# StarFive VisionFive 2 v1.3b register map
File version: 0.1
Registers are 32-bit, read-write, no defined reset value unless marked. A register's access mark holds for its fields unless they carry their own. Offsets are from the block's base; [hi:lo] are bit positions; {n}, {i} and the like mark numbered series.

## starfive_jh7110_aon_pinctrl_0 — From starfive,jh7110-aon-pinctrl, peripheral generator
Base 0x17020000
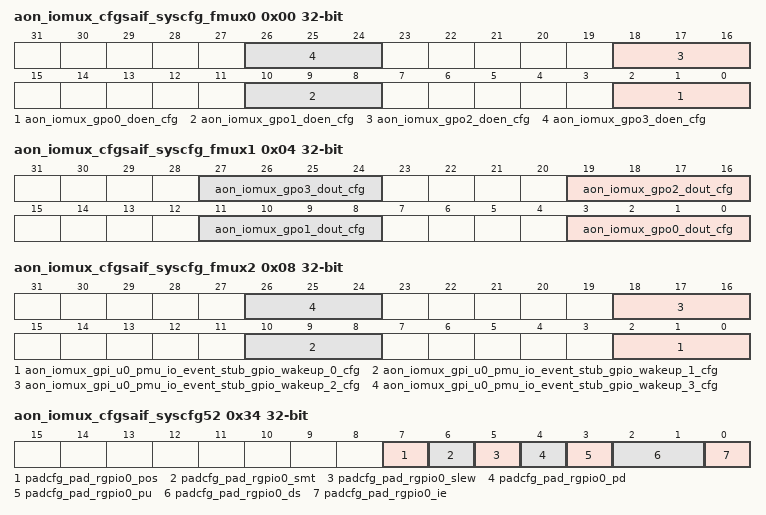
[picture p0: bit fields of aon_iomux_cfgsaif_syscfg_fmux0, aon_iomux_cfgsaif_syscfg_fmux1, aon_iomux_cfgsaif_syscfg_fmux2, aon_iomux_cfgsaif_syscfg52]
0x00 aon_iomux_cfgsaif_syscfg_fmux0
  [8n+2:8n] aon_iomux_gpo{n}_doen_cfg (n=0..3) — The selected OEN signal for GPIO{n}. The register value indicates the selected GPIO (Output Enable) OEN index from GPIO OEN list 0-5. See Table 2-42: GPIO OEN List for AON_IOMUX for more information.
0x04 aon_iomux_cfgsaif_syscfg_fmux1
  [8n+3:8n] aon_iomux_gpo{n}_dout_cfg (n=0..3) — The selected OEN signal for GPIO{n}. The register value indicates the selected GPIO output signal list 0-9. See Table 2-42: GPIO OEN List for AON_IOMUX for more information.
0x08 aon_iomux_cfgsaif_syscfg_fmux2
  [8n+2:8n] aon_iomux_gpi_u0_pmu_io_event_stub_gpio_wakeup_{n}_cfg (n=0..3) — The register value indicates the selected GPIO number + 2 (GPIO2-GPIO63, GPIO0 and GPIO1 are not available) for the input signal.
0x0C aon_iomux_cfgsaif_syscfg_fmux3
  [0] aon_gpioen_0_reg — Enable GPIO IRQ function.
0x10 aon_iomux_cfgsaif_syscfg_ioirq4
  [3:0] aon_gpiois_0_reg — 1: Edge trigger, 0: Level trigger
0x14 aon_iomux_cfgsaif_syscfg_ioirq5
  [3:0] aon_gpioic_0_reg — 1: Do not clear the register, 0: Clear the register
0x18 aon_iomux_cfgsaif_syscfg_ioirq6
  [3:0] aon_gpioibe_0_reg — 1: Trigger on both edges, 0: Trigger on a single edge
0x1C aon_iomux_cfgsaif_syscfg_ioirq7
  [3:0] aon_gpioiev_0_reg — 1: Positive/Low, 0: Negative/High
0x20 aon_iomux_cfgsaif_syscfg_ioirq8
  [3:0] aon_gpioie_0_reg — 1: Unmask, 0: Mask
0x24 aon_iomux_cfgsaif_syscfg_ioirq9
  [3:0] aon_gpioris_0_reg ro — Status of the edge trigger, can be cleared by writing gpioic.
0x28 aon_iomux_cfgsaif_syscfg_ioirq10
  [3:0] aon_gpiomis_0_reg ro — The masked GPIO IRQ status.
0x2C aon_iomux_cfgsaif_syscfg_ioirq11
  [3:0] aon_gpio_in_sync2_0_reg ro — Status of gpio_in after synchronization.
0x30 aon_iomux_cfgsaif_syscfg48
  [0] padcfg_pad_testen_pos — Power-on-Start (POS) enabler - 1: Enable active pull down for loss of core power, 0: Active pull-down capability disabled
0x34 aon_iomux_cfgsaif_syscfg52
  [7] padcfg_pad_rgpio0_pos — Power-on-Start (POS) enabler - 1: Enable active pull down for loss of core power, 0: Active pull-down capability disabled
  [6] padcfg_pad_rgpio0_smt — Active high Schmitt (SMT) trigger selector - 0: No hysteresis, 1: Schmitt trigger ebabled
  [5] padcfg_pad_rgpio0_slew — Slew Rate Control - 0: Slow (Half frequency), 1: Fast
  [4] padcfg_pad_rgpio0_pd — Pull-Down (PD) settings - 1: Yes, 0: No
  [3] padcfg_pad_rgpio0_pu — Pull-Up (PU) settings - 1: Yes, 0: No
  [2:1] padcfg_pad_rgpio0_ds — Output Drive Strength (DS) - 00: The rated drive strength is 2 mA, 01: The rated drive strength is 4 mA, 10: The rated drive strength is 8 mA, 11: The rated drive strength is 12 mA
  [0] padcfg_pad_rgpio0_ie — Input Enable (IE) Controller - 1: Enable the receiver, 0: Disable the receiver
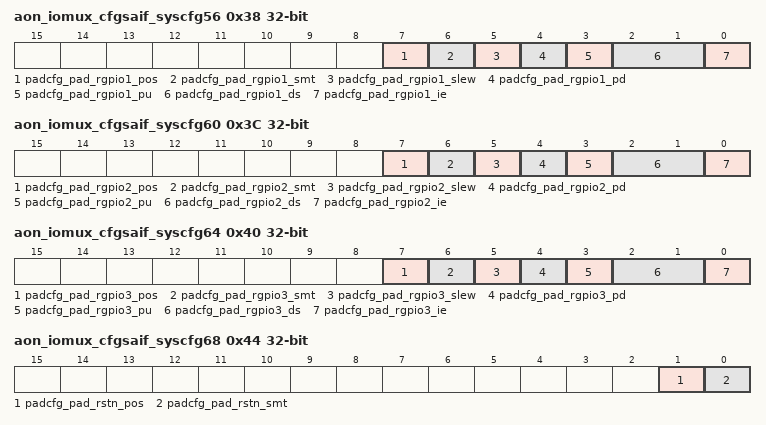
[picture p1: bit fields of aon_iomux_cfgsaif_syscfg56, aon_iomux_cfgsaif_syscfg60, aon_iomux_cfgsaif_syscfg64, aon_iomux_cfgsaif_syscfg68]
0x38 aon_iomux_cfgsaif_syscfg56
  [7] padcfg_pad_rgpio1_pos — Power-on-Start (POS) enabler - 1: Enable active pull down for loss of core power, 0: Active pull-down capability disabled
  [6] padcfg_pad_rgpio1_smt — Active high Schmitt (SMT) trigger selector - 0: No hysteresis, 1: Schmitt trigger ebabled
  [5] padcfg_pad_rgpio1_slew — Slew Rate Control - 0: Slow (Half frequency), 1: Fast
  [4] padcfg_pad_rgpio1_pd — Pull-Down (PD) settings - 1: Yes, 0: No
  [3] padcfg_pad_rgpio1_pu — Pull-Up (PU) settings - 1: Yes, 0: No
  [2:1] padcfg_pad_rgpio1_ds — Output Drive Strength (DS) - 00: The rated drive strength is 2 mA, 01: The rated drive strength is 4 mA, 10: The rated drive strength is 8 mA, 11: The rated drive strength is 12 mA
  [0] padcfg_pad_rgpio1_ie — Input Enable (IE) Controller - 1: Enable the receiver, 0: Disable the receiver
0x3C aon_iomux_cfgsaif_syscfg60
  [7] padcfg_pad_rgpio2_pos — Power-on-Start (POS) enabler - 1: Enable active pull down for loss of core power, 0: Active pull-down capability disabled
  [6] padcfg_pad_rgpio2_smt — Active high Schmitt (SMT) trigger selector - 0: No hysteresis, 1: Schmitt trigger ebabled
  [5] padcfg_pad_rgpio2_slew — Slew Rate Control - 0: Slow (Half frequency), 1: Fast
  [4] padcfg_pad_rgpio2_pd — Pull-Down (PD) settings - 1: Yes, 0: No
  [3] padcfg_pad_rgpio2_pu — Pull-Up (PU) settings - 1: Yes, 0: No
  [2:1] padcfg_pad_rgpio2_ds — Output Drive Strength (DS) - 00: The rated drive strength is 2 mA, 01: The rated drive strength is 4 mA, 10: The rated drive strength is 8 mA, 11: The rated drive strength is 12 mA
  [0] padcfg_pad_rgpio2_ie — Input Enable (IE) Controller - 1: Enable the receiver, 0: Disable the receiver
0x40 aon_iomux_cfgsaif_syscfg64
  [7] padcfg_pad_rgpio3_pos — Power-on-Start (POS) enabler - 1: Enable active pull down for loss of core power, 0: Active pull-down capability disabled
  [6] padcfg_pad_rgpio3_smt — Active high Schmitt (SMT) trigger selector - 0: No hysteresis, 1: Schmitt trigger ebabled
  [5] padcfg_pad_rgpio3_slew — Slew Rate Control - 0: Slow (Half frequency), 1: Fast
  [4] padcfg_pad_rgpio3_pd — Pull-Down (PD) settings - 1: Yes, 0: No
  [3] padcfg_pad_rgpio3_pu — Pull-Up (PU) settings - 1: Yes, 0: No
  [2:1] padcfg_pad_rgpio3_ds — Output Drive Strength (DS) - 00: The rated drive strength is 2 mA, 01: The rated drive strength is 4 mA, 10: The rated drive strength is 8 mA, 11: The rated drive strength is 12 mA
  [0] padcfg_pad_rgpio3_ie — Input Enable (IE) Controller - 1: Enable the receiver, 0: Disable the receiver
0x44 aon_iomux_cfgsaif_syscfg68
  [1] padcfg_pad_rstn_pos — Power-on-Start (POS) enabler - 1: Enable active pull-down for loss of core power, 0: Active pull-down capability disabled
  [0] padcfg_pad_rstn_smt — Active high Schmitt (SMT) trigger selector - 0: No hysteresis, 1: Schmitt trigger enabled
0x4C aon_iomux_cfgsaif_syscfg76
  [1:0] padcfg_pad_rtc_ds — Output Drive Strength (DS): * 00: The rated drive strength is 2 mA. * 01: The rated drive strength is 4 mA. * 10: The rated drive strength is 8 mA. * 11: The rated drive strength is 12 mA.
0x54 aon_iomux_cfgsaif_syscfg84
  [1:0] padcfg_pad_osc_ds — Output Drive Strength (DS): * 00: The rated drive strength is 2 mA. * 01: The rated drive strength is 4 mA. * 10: The rated drive strength is 8 mA. * 11: The rated drive strength is 12 mA.
0x58 aon_iomux_cfgsaif_syscfg88
  [1:0] padcfg_pad_gmac0_mdc_syscon
0x5C aon_iomux_cfgsaif_syscfg92
  [1:0] padcfg_pad_gmac0_mdio_syscon
0x60 aon_iomux_cfgsaif_syscfg96
  [1:0] padcfg_pad_gmac0_rxd0_syscon — 0: GMAC0 IO voltage select 3.3V, 1: GMAC0 IO voltage select 2.5V, 2: GMAC0 IO voltage select 1.8V
0x64 aon_iomux_cfgsaif_syscfg100
  [1:0] padcfg_pad_gmac0_rxd1_syscon
0x68 aon_iomux_cfgsaif_syscfg104
  [1:0] padcfg_pad_gmac0_rxd2_syscon
0x6C aon_iomux_cfgsaif_syscfg108
  [1:0] padcfg_pad_gmac0_rxd3_syscon
0x70 aon_iomux_cfgsaif_syscfg112
  [1:0] padcfg_pad_gmac0_rxdv_syscon
0x74 aon_iomux_cfgsaif_syscfg116
  [1:0] padcfg_pad_gmac0_rxc_syscon
0x78 aon_iomux_cfgsaif_syscfg120
  [1:0] padcfg_pad_gmac0_txd0_syscon
0x7C aon_iomux_cfgsaif_syscfg124
  [1:0] padcfg_pad_gmac0_txd1_syscon
0x80 aon_iomux_cfgsaif_syscfg128
  [1:0] padcfg_pad_gmac0_txd2_syscon
0x84 aon_iomux_cfgsaif_syscfg132
  [1:0] padcfg_pad_gmac0_txd3_syscon
0x88 aon_iomux_cfgsaif_syscfg136
  [1:0] padcfg_pad_gmac0_txen_syscon
0x8C aon_iomux_cfgsaif_syscfg140
  [1:0] padcfg_pad_gmac0_txc_syscon
0x90 aon_iomux_cfgsaif_syscfg144
  [1:0] pad_gmac0_rxc_func_sel — Function selector of GMAC0_RXC: * Function 0: u0_aon_crg_clk_gmac0_rgmii_rx, * Function 1: u0_aon_crg_clk_gmac0_rmii_ref, * Function 2: None, * Function 3: None
